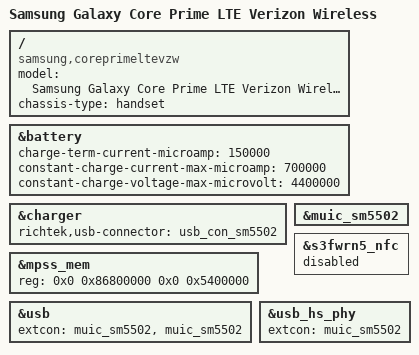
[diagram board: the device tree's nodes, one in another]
// SPDX-License-Identifier: GPL-2.0-only

/dts-v1/;

#include "msm8916-samsung-rossa-common.dtsi"

/ {
	model = "Samsung Galaxy Core Prime LTE Verizon Wireless";
	compatible = "samsung,coreprimeltevzw", "qcom,msm8916";
	chassis-type = "handset";
};

&battery {
	charge-term-current-microamp = <150000>;
	constant-charge-current-max-microamp = <700000>;
	constant-charge-voltage-max-microvolt = <4400000>;
};

&charger {
	richtek,usb-connector = <&usb_con_sm5502>;
	status = "okay";
};

&mpss_mem {
	/* Firmware for coreprimeltevzw needs more space */
	reg = <0x0 0x86800000 0x0 0x5400000>;
};

&muic_sm5502 {
	status = "okay";
};

&s3fwrn5_nfc {
	status = "disabled";
};

&usb {
	extcon = <&muic_sm5502>, <&muic_sm5502>;
	status = "okay";
};

&usb_hs_phy {
	extcon = <&muic_sm5502>;
};
